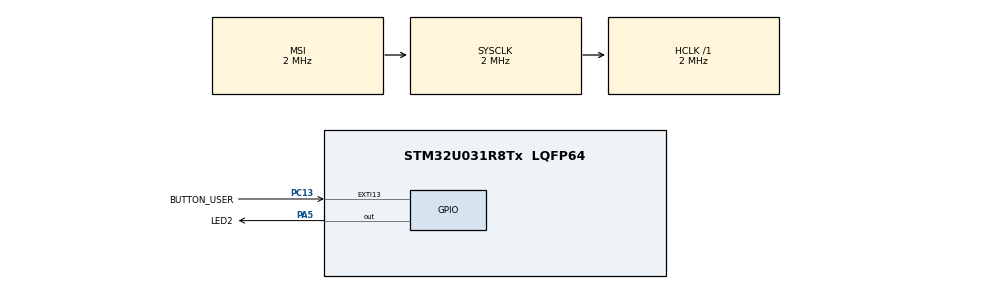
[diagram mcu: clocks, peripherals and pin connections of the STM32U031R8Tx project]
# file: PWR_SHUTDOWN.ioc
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Mcu.Family=STM32U0
Mcu.Name=STM32U031R8Tx
Mcu.Package=LQFP64
NVIC.EXTI4_15_IRQn=true\:0\:0\:false\:false\:true\:true\:true\:true
NVIC.PriorityGroup=NVIC_PRIORITYGROUP_2
PA5.GPIO_Label=LED2
PA5.Signal=GPIO_Output
PC13.GPIO_Label=BUTTON_USER
PC13.GPIO_ModeDefaultEXTI=GPIO_MODE_IT_FALLING
PC13.GPIO_PuPd=GPIO_PULLUP
PC13.Signal=GPXTI13
ProjectManager.HeapSize=0x200
ProjectManager.StackSize=0x400
ProjectManager.TargetToolchain=EWARM V9.20
RCC.ADCFreq_Value=2000000
RCC.AHBFreq_Value=2000000
RCC.CortexFreq_Value=2000000
RCC.HCLKFreq_Value=2000000
RCC.HSE_VALUE=4000000
RCC.HSI48_VALUE=48000000
RCC.HSI_VALUE=16000000
RCC.LSE_VALUE=32768
RCC.MSIClockRangeVal=RCC_MSIRANGE_5
RCC.MSI_VALUE=2000000
RCC.PLLM=RCC_PLLM_DIV8
RCC.PLLN=8
RCC.PLLSourceVirtual=RCC_PLLSOURCE_MSI
RCC.SYSCLKFreq_VALUE=2000000
RCC.SYSCLKSource=RCC_SYSCLKSOURCE_MSI
RCC.USBFreq_Value=48000000
RCC.VCOOutputFreq_Value=2000000
VP_PWR_VS_SECSignals.Mode=Security/Privilege
board=NUCLEO-U031R8

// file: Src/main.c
/* USER CODE BEGIN Header */
/**
  ******************************************************************************
  * @file           : main.c
  * @brief          : Main program body
  ******************************************************************************
  * @attention
  *
  * Copyright (c) 2023 STMicroelectronics.
  * All rights reserved.
  *
  * This software is licensed under terms that can be found in the LICENSE file
  * in the root directory of this software component.
  * If no LICENSE file comes with this software, it is provided AS-IS.
  *
  ******************************************************************************
  */
/* USER CODE END Header */
#include "main.h"

/* USER CODE BEGIN Includes */
#include "stm32u0xx_nucleo.h"
/* USER CODE END Includes */

/* USER CODE BEGIN PV */
/* Private variables ---------------------------------------------------------*/
/* Delay set between each LED turn-on/off while LED is toggling */
#define LED_TOGGLE_DELAY         100
/* Delay set to keep LED turned on when out-of-shutdown detected */
#define LED_FREEZE_DELAY         50

static __IO uint32_t TimingDelay;
static __IO uint32_t counter;             /* ad-hoc counter set to keep LED
                                             on for about 4 sec. when out-of-
                                             shutdown exit detected */
static __IO uint32_t out_of_shutdown;     /* flag initialized at 0, set when
                                             exit from shutdown detected */

/* USER CODE END PV */

void SystemClock_Config(void);
static void MX_GPIO_Init(void);
/* USER CODE BEGIN PFP */
/* Private function prototypes -----------------------------------------------*/

/* USER CODE END PFP */

int main(void)
{

  /* USER CODE BEGIN 1 */
  out_of_shutdown = 0;
  counter = LED_FREEZE_DELAY;

  /* USER CODE END 1 */

  /* MCU Configuration--------------------------------------------------------*/

  /* Reset of all peripherals, Initializes the Flash interface and the Systick. */
  HAL_Init();

  /* Configure the system clock */
  SystemClock_Config();

  /* Initialize all configured peripherals */
  MX_GPIO_Init();
  /* USER CODE BEGIN 2 */

   /* Configure User push-button : required when exiting shutdown mode*/
  BSP_PB_Init(BUTTON_USER, BUTTON_MODE_EXTI);

   /* Enable Power Clock */
  __HAL_RCC_PWR_CLK_ENABLE();
  HAL_PWR_EnableBkUpAccess();

    /* Check if the system was resumed from shutdown mode,
     resort to RTC-TAMP back-up register BKP15R to verify
     whether or not shutdown entry flag was set by software
     before entering shutdown mode.  */
  if (READ_REG(TAMP->BKP1R) == 1)
  {
     WRITE_REG( TAMP->BKP1R, 0x0 );  /* reset back-up register */
     out_of_shutdown = 1;            /* out of shutdown detected */
    /* Wait that user release the User push-button */
    BSP_PB_Init(BUTTON_USER, BUTTON_MODE_GPIO);
    while(BSP_PB_GetState(BUTTON_USER) == GPIO_PIN_RESET){}
  }

   /* Check and Clear the Wakeup flag */
  if (__HAL_PWR_GET_FLAG(PWR_FLAG_WUF2) != RESET)
  {
    __HAL_PWR_CLEAR_FLAG(PWR_FLAG_WUF2);
  }

  /* Initialize the User push-button to generate external interrupts */
  BSP_PB_Init(BUTTON_USER, BUTTON_MODE_EXTI);

  /* Turn on LED4 */
  BSP_LED_On(LED4);

  /* USER CODE END 2 */

  /* Infinite loop */
  while (1)
  {

  }
}

void SystemClock_Config(void)
{
  RCC_OscInitTypeDef RCC_OscInitStruct = {0};
  RCC_ClkInitTypeDef RCC_ClkInitStruct = {0};

  /** Configure the main internal regulator output voltage
  */
  HAL_PWREx_ControlVoltageScaling(PWR_REGULATOR_VOLTAGE_SCALE2);

  /** Initializes the RCC Oscillators according to the specified parameters
  * in the RCC_OscInitTypeDef structure.
  */
  RCC_OscInitStruct.OscillatorType = RCC_OSCILLATORTYPE_MSI;
  RCC_OscInitStruct.MSIState = RCC_MSI_ON;
  RCC_OscInitStruct.MSICalibrationValue = RCC_MSICALIBRATION_DEFAULT;
  RCC_OscInitStruct.MSIClockRange = RCC_MSIRANGE_5;
  RCC_OscInitStruct.PLL.PLLState = RCC_PLL_NONE;
  if (HAL_RCC_OscConfig(&RCC_OscInitStruct) != HAL_OK)
  {
    Error_Handler();
  }

  /** Initializes the CPU, AHB and APB buses clocks
  */
  RCC_ClkInitStruct.ClockType = RCC_CLOCKTYPE_HCLK|RCC_CLOCKTYPE_SYSCLK
                              |RCC_CLOCKTYPE_PCLK1;
  RCC_ClkInitStruct.SYSCLKSource = RCC_SYSCLKSOURCE_MSI;
  RCC_ClkInitStruct.AHBCLKDivider = RCC_SYSCLK_DIV1;
  RCC_ClkInitStruct.APB1CLKDivider = RCC_HCLK_DIV1;

  if (HAL_RCC_ClockConfig(&RCC_ClkInitStruct, FLASH_LATENCY_0) != HAL_OK)
  {
    Error_Handler();
  }
}

static void MX_GPIO_Init(void)
{
  GPIO_InitTypeDef GPIO_InitStruct = {0};

  /* GPIO Ports Clock Enable */
  __HAL_RCC_GPIOC_CLK_ENABLE();
  __HAL_RCC_GPIOA_CLK_ENABLE();

  /*Configure GPIO pin Output Level */
  HAL_GPIO_WritePin(LED2_GPIO_Port, LED2_Pin, GPIO_PIN_RESET);

  /*Configure GPIO pin : BUTTON_USER_Pin */
  GPIO_InitStruct.Pin = BUTTON_USER_Pin;
  GPIO_InitStruct.Mode = GPIO_MODE_IT_FALLING;
  GPIO_InitStruct.Pull = GPIO_PULLUP;
  HAL_GPIO_Init(BUTTON_USER_GPIO_Port, &GPIO_InitStruct);

  /*Configure GPIO pin : LED2_Pin */
  GPIO_InitStruct.Pin = LED2_Pin;
  GPIO_InitStruct.Mode = GPIO_MODE_OUTPUT_PP;
  GPIO_InitStruct.Pull = GPIO_NOPULL;
  GPIO_InitStruct.Speed = GPIO_SPEED_FREQ_LOW;
  HAL_GPIO_Init(LED2_GPIO_Port, &GPIO_InitStruct);

  /* EXTI interrupt init*/
  HAL_NVIC_SetPriority(EXTI4_15_IRQn, 0, 0);
  HAL_NVIC_EnableIRQ(EXTI4_15_IRQn);

}

/* USER CODE BEGIN 4 */

/**
  * @brief SYSTICK callback
  * @param None
  * @retval None
  */
void HAL_SYSTICK_Callback(void)
{
  if (TimingDelay != 0)
  {
    TimingDelay--;
  }
  else
  {
    /* Keep LED4 on for about 4 sec. when out-of-shutdown detected */
    if ((out_of_shutdown == 1) && (counter > 0))
    {
      BSP_LED_On(LED4);
      counter--;
    }
    else
    {
    /* Toggle LED4 */
    BSP_LED_Toggle(LED4);
    }
    TimingDelay = LED_TOGGLE_DELAY;
  }
}

/**
  * @brief EXTI line detection callbacks
  * @param GPIO_Pin: Specifies the pins connected EXTI line
  * @retval None
  */
void HAL_GPIO_EXTI_Falling_Callback(uint16_t GPIO_Pin)
{
  if (GPIO_Pin == BUTTON_USER_PIN)
  {
    /* Wait that user release the User push-button */
    while(BSP_PB_GetState(BUTTON_USER) == GPIO_PIN_RESET){}

   /* Enable wakeup pin WKUP2 */
    HAL_PWR_EnableWakeUpPin(PWR_WAKEUP_PIN2_LOW);

    /* Configure PullUp mode for the wakeup pin WKUP2/PC13 */
    HAL_PWREx_EnablePullUpPullDownConfig();
    HAL_PWREx_EnableGPIOPullUp(PWR_GPIO_C, GPIO_PIN_13);

    /* Clear wake up Flag */
    __HAL_PWR_CLEAR_FLAG(PWR_FLAG_WUF2);

    /* Set RTC-TAMP back-up register BKP15R to indicate
       later on that system has entered shutdown mode  */
    WRITE_REG( TAMP->BKP1R, 0x1 );
    HAL_SuspendTick();
    /* Enter shutdown mode */
    HAL_PWR_EnterSHUTDOWNMode();
  }
}
/* USER CODE END 4 */

void Error_Handler(void)
{
  __disable_irq();
  while (1)
  {
  }
}
